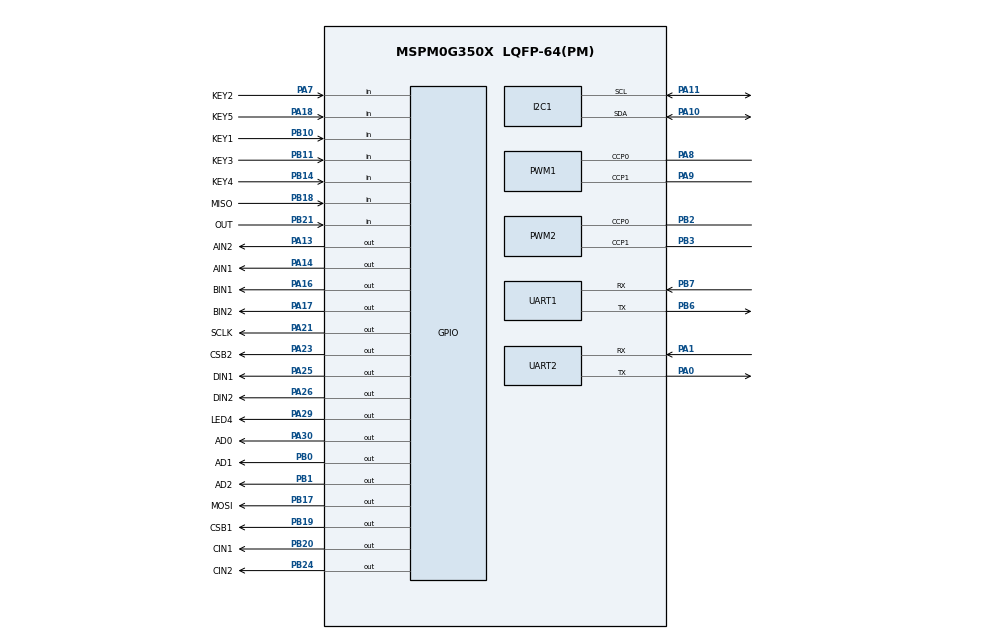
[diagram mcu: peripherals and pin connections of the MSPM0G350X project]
/**
 * @cliArgs --device "MSPM0G350X" --part "Default" --package "LQFP-64(PM)" --product "mspm0_sdk@2.11.00.07"
 * @versions {"tool":"1.26.2+4477"}
 */

/**
 * Import the modules used in this configuration.
 */
const GPIO          = scripting.addModule("/ti/driverlib/GPIO", {}, false);
const GPIO1         = GPIO.addInstance();
const GPIO2         = GPIO.addInstance();
const GPIO3         = GPIO.addInstance();
const GPIO4         = GPIO.addInstance();
const GPIO5         = GPIO.addInstance();
const GPIO6         = GPIO.addInstance();
const GPIO7         = GPIO.addInstance();
const GPIO8         = GPIO.addInstance();
const GPIO9         = GPIO.addInstance();
const I2C           = scripting.addModule("/ti/driverlib/I2C", {}, false);
const I2C1          = I2C.addInstance();
const PWM           = scripting.addModule("/ti/driverlib/PWM", {}, false);
const PWM1          = PWM.addInstance();
const PWM2          = PWM.addInstance();
const SYSCTL        = scripting.addModule("/ti/driverlib/SYSCTL");
const UART          = scripting.addModule("/ti/driverlib/UART", {}, false);
const UART1         = UART.addInstance();
const UART2         = UART.addInstance();
const ProjectConfig = scripting.addModule("/ti/project_config/ProjectConfig");

/**
 * Write custom configuration values to the imported modules.
 */
GPIO1.$name                         = "GPIO_KEY_B";
GPIO1.port                          = "PORTB";
GPIO1.associatedPins.create(3);
GPIO1.associatedPins[0].$name       = "KEY1";
GPIO1.associatedPins[0].direction   = "INPUT";
GPIO1.associatedPins[0].pin.$assign = "PB10";
GPIO1.associatedPins[1].$name       = "KEY3";
GPIO1.associatedPins[1].direction   = "INPUT";
GPIO1.associatedPins[1].pin.$assign = "PB11";
GPIO1.associatedPins[2].$name       = "KEY4";
GPIO1.associatedPins[2].direction   = "INPUT";
GPIO1.associatedPins[2].pin.$assign = "PB14";

const Board = scripting.addModule("/ti/driverlib/Board", {}, false);

GPIO2.$name                              = "GPIO_KEYA";
GPIO2.port                               = "PORTA";
GPIO2.associatedPins.create(2);
GPIO2.associatedPins[0].$name            = "KEY2";
GPIO2.associatedPins[0].direction        = "INPUT";
GPIO2.associatedPins[0].pin.$assign      = "PA7";
GPIO2.associatedPins[1].$name            = "KEY5";
GPIO2.associatedPins[1].direction        = "INPUT";
GPIO2.associatedPins[1].internalResistor = "PULL_UP";
GPIO2.associatedPins[1].pin.$assign      = "PA18";

GPIO3.$name                         = "GPIO_DIRA";
GPIO3.port                          = "PORTA";
GPIO3.associatedPins.create(6);
GPIO3.associatedPins[0].$name       = "AIN2";
GPIO3.associatedPins[0].pin.$assign = "PA13";
GPIO3.associatedPins[1].$name       = "AIN1";
GPIO3.associatedPins[1].pin.$assign = "PA14";
GPIO3.associatedPins[2].$name       = "BIN2";
GPIO3.associatedPins[2].pin.$assign = "PA17";
GPIO3.associatedPins[3].$name       = "BIN1";
GPIO3.associatedPins[3].pin.$assign = "PA16";
GPIO3.associatedPins[4].$name       = "DIN2";
GPIO3.associatedPins[4].pin.$assign = "PA26";
GPIO3.associatedPins[5].$name       = "DIN1";
GPIO3.associatedPins[5].pin.$assign = "PA25";

GPIO4.$name                         = "GPIO_DIRB";
GPIO4.port                          = "PORTB";
GPIO4.associatedPins.create(2);
GPIO4.associatedPins[0].$name       = "CIN2";
GPIO4.associatedPins[0].pin.$assign = "PB24";
GPIO4.associatedPins[1].$name       = "CIN1";
GPIO4.associatedPins[1].pin.$assign = "PB20";

GPIO5.$name                              = "GPIO_IMU_B";
GPIO5.port                               = "PORTB";
GPIO5.associatedPins.create(3);
GPIO5.associatedPins[0].$name            = "MOSI";
GPIO5.associatedPins[0].pin.$assign      = "PB17";
GPIO5.associatedPins[1].$name            = "MISO";
GPIO5.associatedPins[1].direction        = "INPUT";
GPIO5.associatedPins[1].internalResistor = "PULL_DOWN";
GPIO5.associatedPins[1].pin.$assign      = "PB18";
GPIO5.associatedPins[2].initialValue     = "SET";
GPIO5.associatedPins[2].$name            = "CSB1";
GPIO5.associatedPins[2].pin.$assign      = "PB19";

GPIO6.$name                          = "GPIO_IMU_A";
GPIO6.port                           = "PORTA";
GPIO6.associatedPins.create(2);
GPIO6.associatedPins[0].$name        = "SCLK";
GPIO6.associatedPins[0].initialValue = "SET";
GPIO6.associatedPins[0].pin.$assign  = "PA21";
GPIO6.associatedPins[1].initialValue = "SET";
GPIO6.associatedPins[1].$name        = "CSB2";
GPIO6.associatedPins[1].pin.$assign  = "PA23";

GPIO7.$name                         = "GPIO_TRACE_B";
GPIO7.port                          = "PORTB";
GPIO7.associatedPins.create(3);
GPIO7.associatedPins[0].$name       = "AD2";
GPIO7.associatedPins[0].pin.$assign = "PB1";
GPIO7.associatedPins[1].$name       = "AD1";
GPIO7.associatedPins[1].pin.$assign = "PB0";
GPIO7.associatedPins[2].$name       = "OUT";
GPIO7.associatedPins[2].direction   = "INPUT";
GPIO7.associatedPins[2].pin.$assign = "PB21";

GPIO8.$name                         = "GPIO_TRACE_A";
GPIO8.port                          = "PORTA";
GPIO8.associatedPins[0].$name       = "AD0";
GPIO8.associatedPins[0].pin.$assign = "PA30";

/* 调试指示灯 LED4（PA29），每收到一帧视觉数据翻转一次 */
GPIO9.$name                         = "GPIO_LED_STATUS";
GPIO9.port                          = "PORTA";
GPIO9.associatedPins.create(1);
GPIO9.associatedPins[0].$name       = "LED4";
GPIO9.associatedPins[0].pin.$assign = "PA29";

I2C1.$name                             = "I2C_OLED";
I2C1.basicEnableController             = true;
I2C1.basicControllerStandardBusSpeed   = "Fast";
I2C1.peripheral.sdaPin.$assign         = "PA10";
I2C1.peripheral.sclPin.$assign         = "PA11";
I2C1.sdaPinConfig.hideOutputInversion  = scripting.forceWrite(false);
I2C1.sdaPinConfig.onlyInternalResistor = scripting.forceWrite(false);
I2C1.sdaPinConfig.passedPeripheralType = scripting.forceWrite("Digital");
I2C1.sdaPinConfig.$name                = "ti_driverlib_gpio_GPIOPinGeneric4";
I2C1.sclPinConfig.hideOutputInversion  = scripting.forceWrite(false);
I2C1.sclPinConfig.onlyInternalResistor = scripting.forceWrite(false);
I2C1.sclPinConfig.passedPeripheralType = scripting.forceWrite("Digital");
I2C1.sclPinConfig.$name                = "ti_driverlib_gpio_GPIOPinGeneric5";

PWM1.timerCount                         = 2133;
PWM1.pwmMode                            = "EDGE_ALIGN_UP";
PWM1.timerStartTimer                    = true;
PWM1.$name                              = "PWM_LEFT";
PWM1.peripheral.ccp0Pin.$assign         = "PA8";
PWM1.peripheral.ccp1Pin.$assign         = "PA9";
PWM1.PWM_CHANNEL_0.$name                = "ti_driverlib_pwm_PWMTimerCC0";
PWM1.PWM_CHANNEL_1.$name                = "ti_driverlib_pwm_PWMTimerCC1";
PWM1.ccp0PinConfig.direction            = scripting.forceWrite("OUTPUT");
PWM1.ccp0PinConfig.hideOutputInversion  = scripting.forceWrite(false);
PWM1.ccp0PinConfig.onlyInternalResistor = scripting.forceWrite(false);
PWM1.ccp0PinConfig.passedPeripheralType = scripting.forceWrite("Digital");
PWM1.ccp0PinConfig.$name                = "ti_driverlib_gpio_GPIOPinGeneric0";
PWM1.ccp1PinConfig.direction            = scripting.forceWrite("OUTPUT");
PWM1.ccp1PinConfig.hideOutputInversion  = scripting.forceWrite(false);
PWM1.ccp1PinConfig.onlyInternalResistor = scripting.forceWrite(false);
PWM1.ccp1PinConfig.passedPeripheralType = scripting.forceWrite("Digital");
PWM1.ccp1PinConfig.$name                = "ti_driverlib_gpio_GPIOPinGeneric1";

PWM2.pwmMode                            = "EDGE_ALIGN_UP";
PWM2.timerStartTimer                    = true;
PWM2.timerCount                         = 2133;
PWM2.$name                              = "PWM_RIGHT";
PWM2.peripheral.ccp0Pin.$assign         = "PB2";
PWM2.peripheral.ccp1Pin.$assign         = "PB3";
PWM2.PWM_CHANNEL_0.$name                = "ti_driverlib_pwm_PWMTimerCC2";
PWM2.PWM_CHANNEL_1.$name                = "ti_driverlib_pwm_PWMTimerCC3";
PWM2.ccp0PinConfig.direction            = scripting.forceWrite("OUTPUT");
PWM2.ccp0PinConfig.hideOutputInversion  = scripting.forceWrite(false);
PWM2.ccp0PinConfig.onlyInternalResistor = scripting.forceWrite(false);
PWM2.ccp0PinConfig.passedPeripheralType = scripting.forceWrite("Digital");
PWM2.ccp0PinConfig.$name                = "ti_driverlib_gpio_GPIOPinGeneric2";
PWM2.ccp1PinConfig.direction            = scripting.forceWrite("OUTPUT");
PWM2.ccp1PinConfig.hideOutputInversion  = scripting.forceWrite(false);
PWM2.ccp1PinConfig.onlyInternalResistor = scripting.forceWrite(false);
PWM2.ccp1PinConfig.passedPeripheralType = scripting.forceWrite("Digital");
PWM2.ccp1PinConfig.$name                = "ti_driverlib_gpio_GPIOPinGeneric3";


UART1.$name                            = "UART_BT";
UART1.enableFIFO                       = true;
UART1.peripheral.$assign               = "UART1";
UART1.peripheral.rxPin.$assign         = "PB7";
UART1.peripheral.txPin.$assign         = "PB6";
UART1.txPinConfig.$name                = "ti_driverlib_gpio_GPIOPinGeneric6";
UART1.txPinConfig.direction            = scripting.forceWrite("OUTPUT");
UART1.txPinConfig.hideOutputInversion  = scripting.forceWrite(false);
UART1.txPinConfig.onlyInternalResistor = scripting.forceWrite(false);
UART1.txPinConfig.passedPeripheralType = scripting.forceWrite("Digital");
UART1.rxPinConfig.$name                = "ti_driverlib_gpio_GPIOPinGeneric7";
UART1.rxPinConfig.hideOutputInversion  = scripting.forceWrite(false);
UART1.rxPinConfig.onlyInternalResistor = scripting.forceWrite(false);
UART1.rxPinConfig.passedPeripheralType = scripting.forceWrite("Digital");

/* 视觉模块 K230：UART0，PA0 = TX，PA1 = RX，115200，开启 RX 中断 */
UART2.$name                            = "UART_VISION";
UART2.peripheral.$assign               = "UART0";
UART2.peripheral.txPin.$assign         = "PA0";
UART2.peripheral.rxPin.$assign         = "PA1";
UART2.targetBaudRate                   = 115200;
UART2.enableFIFO                       = true;
UART2.rxFifoThreshold                  = "DL_UART_RX_FIFO_LEVEL_ONE_ENTRY";
UART2.enabledInterrupts                = ["RX"];

ProjectConfig.deviceSpin = "MSPM0G3507";

/**
 * Pinmux solution for unlocked pins/peripherals. This ensures that minor changes to the automatic solver in a future
 * version of the tool will not impact the pinmux you originally saw.  These lines can be completely deleted in order to
 * re-solve from scratch.
 */
Board.peripheral.$suggestSolution          = "DEBUGSS";
Board.peripheral.swclkPin.$suggestSolution = "PA20";
Board.peripheral.swdioPin.$suggestSolution = "PA19";
I2C1.peripheral.$suggestSolution           = "I2C0";
PWM1.peripheral.$suggestSolution           = "TIMA0";
PWM2.peripheral.$suggestSolution           = "TIMA1";
SYSCTL.peripheral.$suggestSolution         = "SYSCTL";
